# SSE300 register map
Vendor: ARM Ltd.; Series: ARMv8.1-M Mainline; File version: 1.0
CPU: CM55 r0p0, little endian, MPU, FPU, 3 interrupt priority bits, 8 SAU regions
Registers are 32-bit, read-write, reset 0x0 unless marked. A register's access mark holds for its fields unless they carry their own. Offsets are from the block's base; [hi:lo] are bit positions; 'fields as' and 'values as' point back to an identical list.

## SYSCOUNTER_CNTRL — System counter control
Base 0x58100000
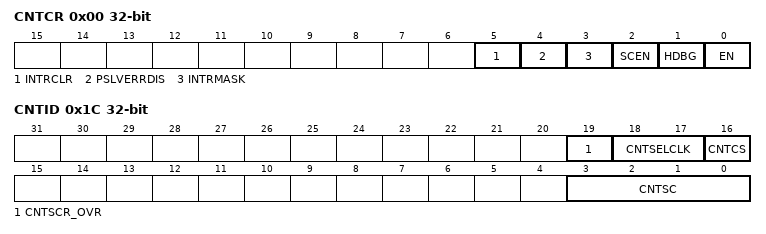
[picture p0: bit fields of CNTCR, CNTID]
0x00 CNTCR — Counter Control Register
  [5] INTRCLR — Interrupt clear bit, only writes of 0 are permitted, and writes of 1 are ignored.
  [4] PSLVERRDIS — PSLVERR output disable
    0=PSLVERRDisabled (PSLVERR is permanently driven to 0); 1=PSLVERREnabled (PSLVERR output that the System Counter generates dynamically)
  [3] INTRMASK — Interrupt mask
    0=InterruptDisabled (Interrupt output disabled); 1=InterruptEnabled (Interrupt output enabled)
  [2] SCEN — Scale enable
    0=ScaleDisabled (Scaling is not enabled); 1=ScaleEnabled (Scaling is enabled)
  [1] HDBG — Halt on debug
    0=Nohalt (HALTREQ signal into the Counter has no effect); 1=HALTREQ signal into the Counter halts the Count
  [0] EN — Enable Counter
    0=Disabled (Count is not incrementing); 1=Enabled (Count is incrementing)
0x04 CNTSR ro — Counter frequency status information
  [4:1] DBGH — Indicates whether the counter is halted because the Halt-on-Debug signal is asserted
    0=Nohalt (Counter is not halted); 1=Halt (Counter is halted)
0x08 CNTCV 64-bit (reset mask 0xFFFFFFFF) — Current count value
  [63:0] Countvalue — Indicates the countvalue
0x10 CNTSCR reset 0x1000000 — Stores the Counter Scaling value
  [31:0] ScaleVal — The amount added to the Counter Count Value for every period of the counter as determined by 1/Frequency from the current operating frequency of the system counter, the counter tick
0x1C CNTID ro — Indicates additional information about Counter Scaling implementation
  [19] CNTSCR_OVR — Override counter enable condition for writing to CNTSCR* registers
    0=COND1 (CNTSCR* can be written only when CNTCR.EN=0); 1=COND2 (CNTSCR* can be written when CNTCR.EN=0 or 1)
  [18:17] CNTSELCLK — Indicates the clock source that the Counter is using
    0=Invalid0 (Invalid status, Counter not incrementing); 1=CLK0 (CLK0 (REFCLK)); 2=CLK1 (CLK1 (FASTCLK)); 3=Invalid1 (Invalid status, Counter not incrementing)
  [16] CNTCS — Indicates whether Clock Switching is implemented
    0=CNTCSNotimplemented (HW-based Counter Clock Switching is not implemented); 1=CNTCSImplemented (HW-based Counter Clock Switching is implemented)
  [3:0] CNTSC — Indicates whether Counter Scaling is implemented
    0=CNTSCNotimplemented (Counter Scaling is not implemented); 1=CNTSCImplemented (Counter Scaling is implemented)
0xD0 CNTSCR0 reset 0x1000000 — Counter Scaling register
  fields as CNTSCR
0xD4 CNTSCR1 reset 0x1000000 — Counter Scaling register
  fields as CNTSCR
0xFD0 CNTPIDR4 ro reset 0x4 — Peripheral Identification Register 4
0xFE0 CNTPIDR0 ro reset 0xBA — Peripheral Identification Register 0
0xFE4 CNTPIDR1 ro reset 0xB0 — Peripheral Identification Register 1
0xFE8 CNTPIDR2 ro reset 0xB — Peripheral Identification Register 2
0xFEC CNTPIDR3 ro — Peripheral Identification Register 3
0xFF0 CNTCIDR0 ro reset 0xD — Component Identification Register 0.
0xFF4 CNTCIDR1 ro reset 0xF0 — Component Identification Register 1
0xFF8 CNTCIDR2 ro reset 0x5 — Component Identification Register 2
0xFFC CNTCIDR3 ro reset 0xB1 — Component Identification Register 3

## SYSCOUNTER_READ — System counter read
Base 0x48101000
Same registers: SYSCOUNTER_READ_Secure 0x58101000
Registers as SYSCOUNTER_CNTRL, without CNTCR, CNTSR, CNTCV, CNTSCR, CNTID, CNTSCR0, CNTSCR1; these are added or differ:
0x00 CNTCV 64-bit (reset mask 0xFFFFFFFF) — Current count value
  [63:0] Countvalue — Indicates the countvalue
0xFE0 CNTPIDR0 ro reset 0xBB — Peripheral Identification Register 0

## SYSINFO — System Information
Base 0x48020000
Same registers: SYSINFO_Secure 0x58020000
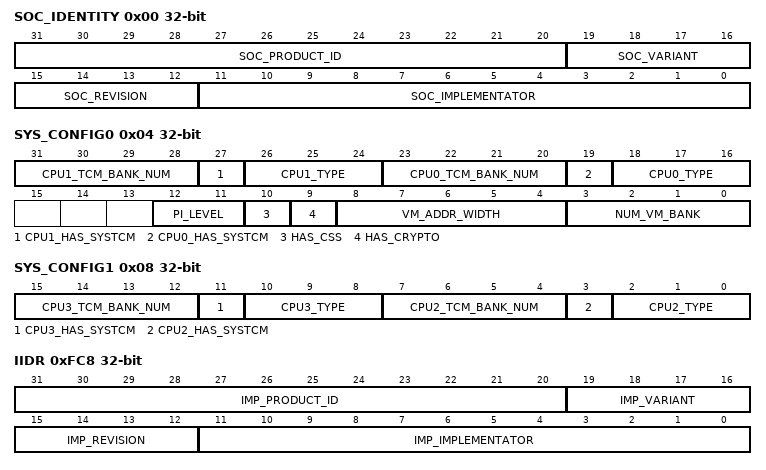
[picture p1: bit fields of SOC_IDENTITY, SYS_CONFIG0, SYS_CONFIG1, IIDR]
0x00 SOC_IDENTITY ro — System Identity Register
  [31:20] SOC_PRODUCT_ID — IMPL_DEF value identifying the SoC.
  [19:16] SOC_VARIANT — IMPL_DEF value variant or major revision of the SoC.
  [15:12] SOC_REVISION — IMPL_DEF value used to distinguish minor revisions of the SoC.
  [11:0] SOC_IMPLEMENTATOR — JEP106 code of the company that implemented the SoC
0x04 SYS_CONFIG0 ro — System Hardware Configuration 0 register
  [31:28] CPU1_TCM_BANK_NUM — The VM Bank that is the TCM memory for CPU 1.
  [27] CPU1_HAS_SYSTCM — CPU 1 has System TCM. Note that this is not the CPU's local ITCM or DTCM, but instead are TCMs implemented at system level.
    0=No (Not included.); 1=Yes (Included.)
  [26:24] CPU1_TYPE — CPU 1 Core Type
    0=No (Does not exist.)
  [23:20] CPU0_TCM_BANK_NUM — The VM Bank that is the TCM memory for CPU 0.
  [19] CPU0_HAS_SYSTCM — CPU 0 has System TCM. Note that this is not the CPU's local ITCM or DTCM, but instead are TCMs implemented at system level.
    0=No (Not included.); 1=Yes (Included.)
  [18:16] CPU0_TYPE — CPU 0 Core Type
    3=CortexM55
  [12:11] PI_LEVEL — Power Infrastructure Level
    1=IntermediateLevel
  [10] HAS_CSS — Include CoreSight SoC-600 based Debug infrastructure.
    0=No (Not included.); 1=Yes (Included.)
  [9] HAS_CRYPTO — CryptoCell Included.
    0=No (CryptoCell Not Included); 1=Yes (CryptoCell Included)
  [8:4] VM_ADDR_WIDTH — Volatile Memory Bank Address Width, where the size of each bank is equal to 2VM_ADDR_WIDTH bytes.
  [3:0] NUM_VM_BANK — Number of Volatile Memory Banks.
0x08 SYS_CONFIG1 ro — System Hardware Configuration 0 register
  [15:12] CPU3_TCM_BANK_NUM — The VM Bank that is the TCM memory for CPU 3.
  [11] CPU3_HAS_SYSTCM — CPU 3 has System TCM. Note that this is not the CPU's local ITCM or DTCM, but instead are TCMs implemented at system level.
    0=No (Not included.); 1=Yes (Included.)
  [10:8] CPU3_TYPE — CPU 3 Core Type.
    0=No (Does not exist.)
  [7:4] CPU2_TCM_BANK_NUM — The VM Bank that is the TCM memory for CPU 2.
  [3] CPU2_HAS_SYSTCM — CPU 2 has System TCM. Note that this is not the CPU's local ITCM or DTCM, but instead are TCMs implemented at system level.
    0=No (Not included.); 1=Yes (Included.)
  [2:0] CPU2_TYPE — CPU 2 Core Type.
    0=No (Does not exist.)
0xFC8 IIDR ro — Subsystem Implementation Identity Register.
  [31:20] IMP_PRODUCT_ID — IMPL_DEF value identifying the subsystem implementation.
  [19:16] IMP_VARIANT — IMPL_DEF value variant or major revision of the subsystem implementation.
  [15:12] IMP_REVISION — IMPL_DEF value used to distinguish minor revisions of the subsystem implementation.
  [11:0] IMP_IMPLEMENTATOR — Contains the JEP106 code of the company that implemented the subsystem implementation.
0xFD0 PIDR4 ro reset 0x4 — Peripheral ID 4
0xFE0 PIDR0 ro reset 0x58 — Peripheral ID 0
0xFE4 PIDR1 ro reset 0xB8 — Peripheral ID 1
0xFE8 PIDR2 ro reset 0x1B — Peripheral ID 2
0xFEC PIDR3 ro — Peripheral ID 3
0xFF0 CIDR0 ro reset 0xD — Component ID 0
0xFF4 CIDR1 ro reset 0xF0 — Component ID 1
0xFF8 CIDR2 ro reset 0x5 — Component ID 2
0xFFC CIDR3 ro reset 0xB1 — Component ID 3

## Notices in the file
Copyright (C) 2012-2022 ARM Limited. All rights reserved.
Purpose: System Viewer Description (SVD) Example (Schema Version 1.1)
This is a description of a none-existent and incomplete device
for demonstration purposes only.
Redistribution and use in source and binary forms, with or without
modification, are permitted provided that the following conditions are met:
- Redistributions of source code must retain the above copyright
notice, this list of conditions and the following disclaimer.
- Redistributions in binary form must reproduce the above copyright
notice, this list of conditions and the following disclaimer in the
documentation and/or other materials provided with the distribution.
- Neither the name of ARM nor the names of its contributors may be used
to endorse or promote products derived from this software without
specific prior written permission.
THIS SOFTWARE IS PROVIDED BY THE COPYRIGHT HOLDERS AND CONTRIBUTORS "AS IS"
AND ANY EXPRESS OR IMPLIED WARRANTIES, INCLUDING, BUT NOT LIMITED TO, THE
IMPLIED WARRANTIES OF MERCHANTABILITY AND FITNESS FOR A PARTICULAR PURPOSE
ARE DISCLAIMED. IN NO EVENT SHALL COPYRIGHT HOLDERS AND CONTRIBUTORS BE
LIABLE FOR ANY DIRECT, INDIRECT, INCIDENTAL, SPECIAL, EXEMPLARY, OR
CONSEQUENTIAL DAMAGES (INCLUDING, BUT NOT LIMITED TO, PROCUREMENT OF
SUBSTITUTE GOODS OR SERVICES; LOSS OF USE, DATA, OR PROFITS; OR BUSINESS
INTERRUPTION) HOWEVER CAUSED AND ON ANY THEORY OF LIABILITY, WHETHER IN
CONTRACT, STRICT LIABILITY, OR TORT (INCLUDING NEGLIGENCE OR OTHERWISE)
ARISING IN ANY WAY OUT OF THE USE OF THIS SOFTWARE, EVEN IF ADVISED OF THE
POSSIBILITY OF SUCH DAMAGE.
